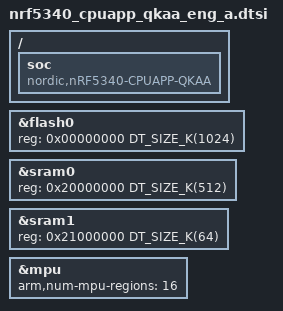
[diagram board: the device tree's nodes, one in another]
/*
 * Copyright (c) 2019 - 2020 Nordic Semiconductor ASA
 *
 * SPDX-License-Identifier: Apache-2.0
 */

#include <mem.h>
#include <nordic/nrf5340_cpuapp.dtsi>

&flash0 {
	reg = <0x00000000 DT_SIZE_K(1024)>;
};

&sram0 {
	reg = <0x20000000 DT_SIZE_K(512)>;
};

&sram1 {
	reg = <0x21000000 DT_SIZE_K(64)>;
};

&mpu {
	arm,num-mpu-regions = <16>;
};

/ {
	soc {
		compatible = "nordic,nRF5340-CPUAPP-QKAA", "nordic,nRF5340-CPUAPP", "nordic,nRF53", "simple-bus";
	};
};

/*
 * Several peripherals are not functional on ENG_A revision
 * so we delete the corresponding DTS nodes.
 */
/delete-node/ &i2c2;
/delete-node/ &i2c3;
/delete-node/ &spi2;
/delete-node/ &spi3;
/delete-node/ &uart2;
/delete-node/ &uart3;
/delete-node/ &usbd;
/delete-node/ &pwm3;
/delete-node/ &wdt1;
